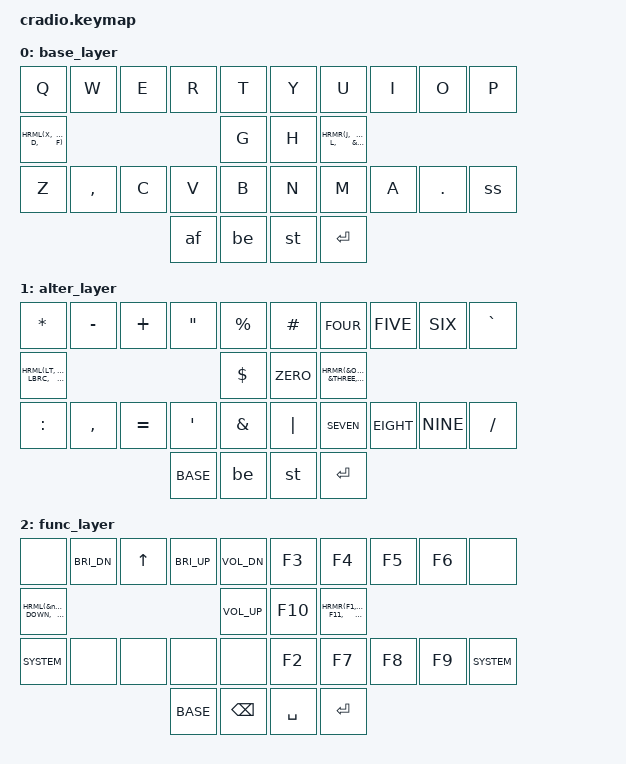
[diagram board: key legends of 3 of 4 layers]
// Copyright (c) 2022 The ZMK Contributors
// SPDX-License-Identifier: MIT

#include <behaviors.dtsi>
#include <dt-bindings/zmk/keys.h>
#include <dt-bindings/zmk/bt.h>

// Home row mods macro
#define HRML(k1,k2,k3,k4) &ht LGUI k1  &ht LALT k2  &ht LCTRL k3  &ht LSHFT k4
#define HRMR(k1,k2,k3,k4) &ht RSHFT k1  &ht RCTRL k2  &ht RALT k3  &ht RGUI k4
#define SHIFTS (MOD_LSFT|MOD_RSFT)

// Layers
#define BASE 0
#define ALTER 1
#define FUNC 2
#define SYSTEM 3

/ {
    behaviors {

        ht: hold_tap {
            compatible = "zmk,behavior-hold-tap";
            #binding-cells = <2>;
            flavor = "tap-preferred";
            tapping-term-ms = <220>;
            quick-tap-ms = <150>;
            require-prior-idle-ms = <100>;
            bindings = <&kp>, <&kp>;
        };

        af: alter_function {
            compatible = "zmk,behavior-mod-morph";
            #binding-cells = <0>;
            bindings = <&kp ALTER>, <&kp FUNC>;
            mods = <SHIFTS>;
        };

        be: backspace_escape {
            compatible = "zmk,behavior-mod-morph";
            #binding-cells = <0>;
            bindings = <&kp BSPC>, <&kp ESC>;
            mods = <SHIFTS>;
        };

        st: space_tab {
            compatible = "zmk,behavior-mod-morph";
            #binding-cells = <0>;
            bindings = <&kp SPACE>, <&kp TAB>;
            mods = <SHIFTS>;
        };

        ss: shift_slash {
            compatible = "zmk,behavior-mod-morph";
            #binding-cells = <0>;
            bindings = <&kp FSLH>, <&kp BSLH>;
            mods = <SHIFTS>;
        };

        uc: underscore_colon {
            compatible = "zmk,behavior-mod-morph";
            #binding-cells = <0>;
            bindings = <&kp UNDER>, <&kp COLON>;
            mods = <SHIFTS>;
        };

        ZERO: caret_zero {
            compatible = "zmk,behavior-mod-morph";
            #binding-cells = <0>;
            bindings = <&kp CARET>, <&kp N0>;
            mods = <SHIFTS>;
        };

        ONE: rpar_one {
            compatible = "zmk,behavior-mod-morph";
            #binding-cells = <0>;
            bindings = <&kp RPAR>, <&kp N1>;
            mods = <SHIFTS>;
        };

        TWO: rbrc_two {
            compatible = "zmk,behavior-mod-morph";
            #binding-cells = <0>;
            bindings = <&kp RBRC>, <&kp N2>;
            mods = <SHIFTS>;
        };

        THREE: rbkt_three {
            compatible = "zmk,behavior-mod-morph";
            #binding-cells = <0>;
            bindings = <&kp RBKT>, <&kp N3>;
            mods = <SHIFTS>;
        };

        FOUR: semi_four {
            compatible = "zmk,behavior-mod-morph";
            #binding-cells = <0>;
            bindings = <&kp SEMI>, <&kp N4>;
            mods = <SHIFTS>;
        };

        FIVE: at_five {
            compatible = "zmk,behavior-mod-morph";
            #binding-cells = <0>;
            bindings = <&kp AT>, <&kp N5>;
            mods = <SHIFTS>;
        };

        SIX: tilde_six {
            compatible = "zmk,behavior-mod-morph";
            #binding-cells = <0>;
            bindings = <&kp TILDE>, <&kp N6>;
            mods = <SHIFTS>;
        };

        SEVEN: excl_seven {
            compatible = "zmk,behavior-mod-morph";
            #binding-cells = <0>;
            bindings = <&kp EXCL>, <&kp N7>;
            mods = <SHIFTS>;
        };

        EIGHT: qmark_eight {
            compatible = "zmk,behavior-mod-morph";
            #binding-cells = <0>;
            bindings = <&kp QMARK>, <&kp N8>;
            mods = <SHIFTS>;
        };

        NINE: dot_nine {
            compatible = "zmk,behavior-mod-morph";
            #binding-cells = <0>;
            bindings = <&kp DOT>, <&kp N9>;
            mods = <SHIFTS>;
        };

    };

    keymap {
        compatible = "zmk,keymap";
        base_layer {
            bindings = <
        //╭──────────┬──────────┬──────────┬──────────┬──────────╮   ╭──────────┬──────────┬──────────┬──────────┬──────────╮
        //│  Q       │  W       │  E       │  R       │  T       │   │  Y       │  U       │  I       │  O       │  P       │
            &kp Q      &kp W      &kp E      &kp R      &kp T          &kp Y      &kp U      &kp I      &kp O      &kp P
        //├──────────┼──────────┼──────────┼──────────┼──────────┤   ├──────────┼──────────┼──────────┼──────────┼──────────┤
        //│  X       │  S       │  D       │  F       │  G       │   │  H       │  J       │  K       │  L       │  _ :     │
            HRML(X,     S,         D,         F)        &kp G          &kp H      HRMR(J,     K,         L,        &uc)
        //├──────────┼──────────┼──────────┼──────────┼──────────┤   ├──────────┼──────────┼──────────┼──────────┼──────────┤
        //│  Z       │  , <     │  C       │  V       │  B       │   │  N       │  M       │  A       │ . >      │ / \      │
            &kp Z      &kp COMMA  &kp C      &kp V      &kp B          &kp N      &kp M      &kp A      &kp DOT    &ss
        //╰──────────┴──────────┴──────────┼──────────┼──────────┤   ├──────────┼──────────┼──────────┴──────────┴──────────╯
                                             &af        &be            &st        &kp ENTER
        //                                 ╰──────────┴──────────╯   ╰──────────┴──────────╯
            >;
        };

        alter_layer {
            bindings = <
        //╭──────────┬──────────┬──────────┬──────────┬──────────╮   ╭──────────┬──────────┬──────────┬──────────┬──────────╮
        //│  *       │  -       │  +       │  "       │  %       │   │  #       │  ; 4     │  @ 5     │  ~ 6     │  `       │
            &kp ASTRK  &kp MINUS  &kp PLUS   &kp DQT    &kp PRCNT      &kp HASH   &FOUR      &FIVE      &SIX       &kp GRAVE
        //├──────────┼──────────┼──────────┼──────────┼──────────┤   ├──────────┼──────────┼──────────┼──────────┼──────────┤
        //│  <       │  [       │  {       │  (       │  $       │   │  ^ 0     │  ) 1     │  } 2     │  ] 3     │  >       │
            HRML(LT,    LBKT,      LBRC,      LPAR)     &kp DLLR       &ZERO      HRMR(&ONE,  &TWO,     &THREE,     GT)
        //├──────────┼──────────┼──────────┼──────────┼──────────┤   ├──────────┼──────────┼──────────┼──────────┼──────────┤
        //│  :       │  ,       │  =       │  '       │  &       │   │  |       │  ! 7     │  ? 8     │  . 9     │  /       │
            &kp COLON &kp COMMA  &kp EQUAL  &kp SQT     &kp AMPS       &kp PIPE   &SEVEN     &EIGHT     &NINE      &kp FSLH
        //╰──────────┴──────────┴──────────┼──────────┼──────────┤   ├──────────┼──────────┼──────────┴──────────┴──────────╯
                                             &kp BASE   &be            &st        &kp ENTER
        //                                 ╰──────────┴──────────╯   ╰──────────┴──────────╯
            >;
        };

        func_layer {
            bindings = <
        //╭──────────┬──────────┬──────────┬──────────┬──────────╮   ╭──────────┬──────────┬──────────┬──────────┬──────────╮
        //│          │  Bri--   │  Up      │  Bri++   │  Vol--   │   │  F3      │  F4      │  F5      │  F6      │          │
            &none      &kp C_BRI_DN &kp UP &kp C_BRI_UP &kp C_VOL_DN   &kp F3     &kp F4     &kp F5     &kp F6     &none
        //├──────────┼──────────┼──────────┼──────────┼──────────┤   ├──────────┼──────────┼──────────┼──────────┼──────────┤
        //│          │  Left    │  Down    │  Right   │  Vol++   │   │  F10     │  F1      │  F12     │  F11     │          │
            HRML(&none, LEFT,      DOWN,      RIGHT)  &kp C_VOL_UP      &kp F10  HRMR(F1,     F12,       F11,      &none)
        //├──────────┼──────────┼──────────┼──────────┼──────────┤   ├──────────┼──────────┼──────────┼──────────┼──────────┤
        //│  SYSTEM  │          │          │          │          │   │  F2      │  F7      │  F8      │  F9      │  SYSTEM  │
           &kp SYSTEM  &none      &none      &none      &none          &kp F2     &kp F7     &kp F8     &kp F9    &kp SYSTEM
        //╰──────────┴──────────┴──────────┼──────────┼──────────┤   ├──────────┼──────────┼──────────┴──────────┴──────────╯
                                             &kp BASE   &kp BSPC       &kp SPACE  &kp ENTER
        //                                 ╰──────────┴──────────╯   ╰──────────┴──────────╯
            >;
        };

        system_layer {
            bindings = <
        //╭──────────┬──────────┬──────────┬──────────┬──────────╮   ╭──────────┬──────────┬──────────┬──────────┬──────────╮
        //│  RESET   │          │          │          │          │   │          │          │                         RESET  │
           &sys_reset  &none      &none      &none      &none          &none      &none      &none      &none     &sys_reset
        //├──────────┼──────────┼──────────┼──────────┼──────────┤   ├──────────┼──────────┼──────────┼──────────┼──────────┤
        //│BOOTLOADER│          │          │          │          │   │                     │          │          │BOOTLOADER│
           &bootloader &none      &none      &none      &none          &none      &none      &none      &none     &bootloader
        //├──────────┼──────────┼──────────┼──────────┼──────────┤   ├──────────┼──────────┼──────────┼──────────┼──────────┤
        //│          │          │          │          │          │   │          │          │          │          │          │
            &none      &none      &none      &none      &none          &none      &none      &none      &none      &none
        //╰──────────┴──────────┴──────────┼──────────┼──────────┤   ├──────────┼──────────┼──────────┴──────────┴──────────╯
                                             &kp BASE   &kp BASE       &kp BASE   &kp BASE 
        //                                 ╰──────────┴──────────╯   ╰──────────┴──────────╯
            >;
        };
    };
};
